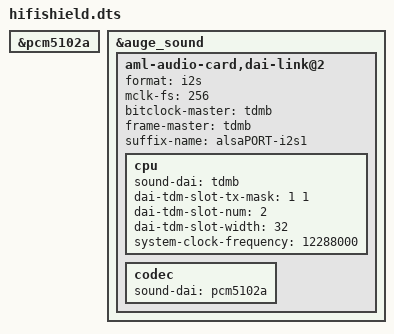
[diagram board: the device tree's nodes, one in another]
/dts-v1/;
/plugin/;

/ {
	fragment@0 {
		target = <&pcm5102a>;
		__overlay__ {
			status = "okay";
		};
	};

	fragment@1 {
		target = <&auge_sound>;
		__overlay__ {
			aml-audio-card,dai-link@2 {
				status = "okay";
				format = "i2s";
				mclk-fs = <256>;
				bitclock-master = <&tdmb>;
				frame-master = <&tdmb>;
				suffix-name = "alsaPORT-i2s1";
				cpu {
					sound-dai = <&tdmb>;
					dai-tdm-slot-tx-mask = <1 1>;
					dai-tdm-slot-num = <2>;
					dai-tdm-slot-width = <32>;
					system-clock-frequency = <12288000>;
				};
				codec {
					sound-dai = <&pcm5102a>;
				};
			};
		};
	};
};
